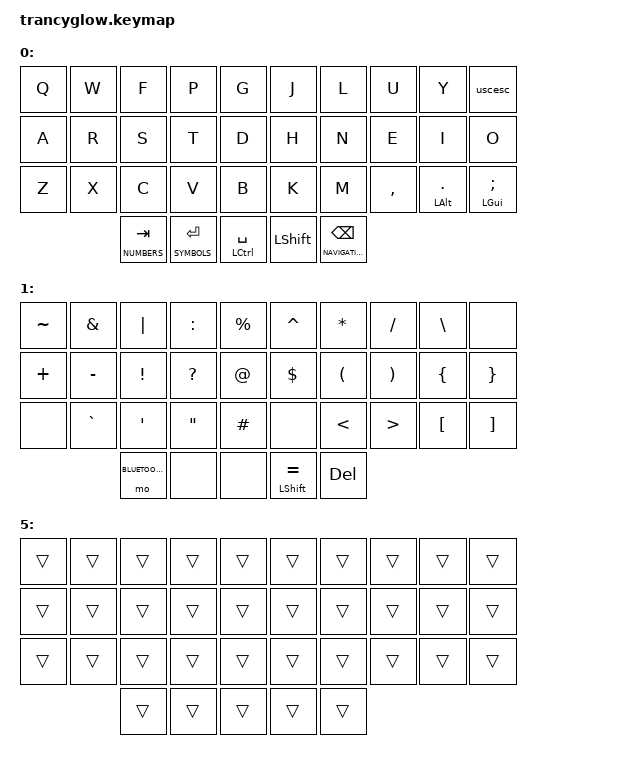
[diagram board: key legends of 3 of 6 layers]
#include <behaviors.dtsi>
#include <input/processors.dtsi>
#include <dt-bindings/zmk/keys.h>
#include <dt-bindings/zmk/bt.h>
#include <dt-bindings/zmk/outputs.h>
#include <dt-bindings/zmk/mouse.h>
#include <dt-bindings/zmk/input_transform.h>
#include <zephyr/dt-bindings/input/input-event-codes.h>

#define SYMBOLS 1
#define NAVIGATION 2
#define NUMBERS 3
#define BLUETOOTH 4
#define MOUSE 5
#define SCROLL 1

&caps_word {
  continue-list = <UNDERSCORE ESC>;
};
        

/ {
        combos {
          compatible = "zmk,combos";

         combo_esc {
           timeout-ms = <50>;
           key-positions = <7 8>;
           bindings = <&kp ESC>;
         };

         combo_back {
           timeout-ms = <50>;
           key-positions = <13 14>;
           bindings = <&mkp MB4>;
         };

         combo_forward {
           timeout-ms = <50>;
           key-positions = <15 16>;
           bindings = <&mkp MB5>;
         };

         combo_lclk {
           timeout-ms = <50>;
           key-positions = <1 2>;
           bindings = <&mkp LCLK>;
         };

         combo_rclk {
           timeout-ms = <50>;
           key-positions = <21 22>;
           bindings = <&mkp RCLK>;
         };

         combo_mclk {
           timeout-ms = <50>;
           key-positions = <27 28>;
           bindings = <&mkp MCLK>;
         };

         combo_shift {
           timeout-ms = <50>;
           key-positions = <17 18>;
           bindings = <&kp LSHIFT>;
           layers = <MOUSE>;
         };

//         combo_delbsps {
//           timeout-ms = <50>;
//           key-positions = <18 19>;
//           bindings = <&delbspc>;
//         };
        };
};
/ {
        behaviors {             
          bhm: balanced_homerow_mods {
            compatible = "zmk,behavior-hold-tap";
            label = "HOMEROW_MODS";
            #binding-cells = <2>;
            tapping-term-ms = <200>; // <---[[moderate duration]]
            quick-tap-ms = <0>;
            flavor = "balanced";
            bindings = <&kp>, <&kp>;
          };

          blt: balanced_layer_tap {
            compatible = "zmk,behavior-hold-tap";
            label = "LAYER_TAPS";
            #binding-cells = <2>;
            tapping-term-ms = <200>;
            quick-tap-ms = <0>;
            flavor = "balanced";
            bindings = <&mo>, <&kp>;
          };
        };

        behaviors {
          delbspc: delete_backspace {
            compatible = "zmk,behavior-mod-morph";
            #binding-cells = <0>;
            bindings = <&blt NAVIGATION BSPC>, <&blt NAVIGATION DEL>;
            mods = <(MOD_LCTL)>;
          };
        };

        behaviors {
          uscesc: underscore_escape {
            compatible = "zmk,behavior-mod-morph";
            #binding-cells = <0>;
            bindings = <&kp ESC>, <&kp UNDERSCORE>;
            mods = <(MOD_LSFT)>;
          };
        };

//        behaviors {
//          ctd: caps_tap_dance {
//            compatible = "zmk,behavior-tap-dance";
//            #binding-cells = <0>;
//            tapping-term-ms = <200>;
//            bindings = <&mo NAVIGATION>, <&caps_word>;
//          };
//        };
#ifdef ZMK_POINTING
        trackball_listener {
            compatible = "zmk,input-listener";
            device = <&trackball_split>;
            input-processors = <&zip_xy_scaler 1 20>,<&zip_xy_scaler 3 1>,<&zip_temp_layer MOUSE 1000>;
 
            scroll {
                layers = <SCROLL>;
                input-processors = <&zip_xy_scaler 1 20>, <&zip_xy_to_scroll_mapper>, <&zip_scroll_transform (INPUT_TRANSFORM_Y_INVERT)>;
            };
        };
#endif
        keymap {
                compatible = "zmk,keymap";
                default_layer { //0
                        label = "";
                        bindings = <
          &kp Q         &kp W       &kp F             &kp P           &kp G               /**/ &kp J            &kp L        &kp U       &kp Y         &uscesc
          &kp A         &kp R       &kp S             &kp T           &kp D               /**/ &kp H            &kp N        &kp E       &kp I         &kp O
          &kp Z         &kp X       &kp C             &kp V           &kp B               /**/ &kp K            &kp M        &kp COMMA   &bhm LALT DOT &bhm LGUI SEMI 
                                         &blt NUMBERS TAB  &blt SYMBOLS RET &bhm LCTRL SPACE   /**/ &kp LSHIFT   &blt NAVIGATION BSPC
                        >;
                };
                lower_layer { //1
                        label = "";
                        bindings = <
        &kp TILDE    &kp AMPS    &kp PIPE    &kp COLON  &kp PRCNT  /**/ &kp CARET  &kp STAR   &kp SLASH &kp BSLH  &none   
        &kp PLUS     &kp MINUS   &kp EXCL    &kp QMARK  &kp AT     /**/ &kp DLLR   &kp LPAR   &kp RPAR  &kp LBRC  &kp RBRC
        &none        &kp GRAVE   &kp APOS    &kp DQT    &kp HASH   /**/ &none      &kp LT     &kp GT    &kp LBKT  &kp RBKT
                           	          &mo BLUETOOTH       &none      &none      /**/ &bhm LSHIFT EQUAL &kp DEL
                        >;
                };

                raise_layer { //2
                  label = "";
                  bindings = <
        &kp LG(LC(Q))      &kp LG(W)  &kp LG(X)  &kp LG(R)         &kp LG(SPACE)      /**/ &kp LG(J)          &none            &kp HOME     &kp END    &none
        &kp LG(N1)         &kp LG(N2) &kp LG(N3) &kp LG(N4)        &kp LG(N5)         /**/ &kp LG(H)     &kp LEFT         &kp DOWN     &kp UP     &kp RIGHT         
        &kp LG(N6)         &kp LG(N7) &kp LG(N8) &kp LG(V)         &kp LG(N0)         /**/ &kp LG(LC(S)) &kp LG(N)        &kp LG(E)    &kp LG(I)  &kp LG(O)             
                                      &kp LG(D)  &kp LG(F)         &bhm LCTRL LG(RET) /**/ &none         &none            &none
                  >;
                };

                prebt_layer { //3
                  label = "";
                  bindings = <
             &kp F1 &kp F2 &kp F3 &kp F4 &kp F5  &kp F6 &kp F7 &kp F8 &kp F9  &kp F10 
             &kp N1 &kp N2 &kp N3 &kp N4 &kp N5  &kp N6 &kp N7 &kp N8 &kp N9  &kp N0  
             &kp F11 &kp F12 &none  &none  &none &none  &none  &none  &none   &none   
                                   &none &none &none   &none &none &mo BLUETOOTH
                  >;
                };

                bt_layer { //4
                  label = "";
                  bindings = <
            &bt BT_SEL 0 &bt BT_SEL 1 &bt BT_SEL 2 &bt BT_SEL 3 &bt BT_CLR   &none &none &none &none &none &tog 6
            &none &none &none &sys_reset &none                                      &none &sys_reset &none &none &none 
            &none &none &none &none &none                                           &none &none &none &none &none 
                              &none &none &none 					      &none &none &none
                  >;
                };

                mouse_layer { //5
                  label = "";
                  bindings = <
                    &trans &trans &trans &trans &trans &trans &trans &trans &trans &trans 
                    &trans &trans &trans &trans &trans &trans &trans &trans &trans &trans 
                    &trans &trans &trans &trans &trans &trans &trans &trans &trans &trans 
                                  &trans &trans &trans &trans &trans 
                  >;
                };

//                empty_layer { //3
//                  label = "";
//                  bindings = <
//   &none      &none   &none      &none     &none     &none     /**/   &none  &none      &none &none     &none     &none
//   &none &none   &none  &none  &none   &none    /**/    &none  &none   &none &none      &none &none
//   &none  &none   &none      &none     &none     &none    /**/    &none  &none &none &none  &none     &none
//                    	          &none     &none     &none     /**/   &none  &none      &none
//                  >;
//                };
//               empty_layer { //6
//                 label = "";
//                 bindings = <
//  &kp TAB      &kp Q   &kp W      &kp E     &kp R     &kp T     /**/   &kp Y  &kp U      &kp I &kp O     &kp P     &tog 6
//  &kp LSHIFT &kp A   &kp S  &kp D  &kp F   &kp G    /**/    &kp H  &kp J   &kp K &kp L      &kp SEMI &kp APOS
//  &kp LCTRL &kp Z   &kp X      &kp C     &kp V     &kp B    /**/    &kp N  &kp M &kp COMMA &kp DOT  &kp SLASH     &none
//                   	          &mo NUMBERS     &mo SYMBOLS     &kp SPACE     /**/   &kp RET  &mo ARROWS      &none


//                 >;
//               };
        };
};
